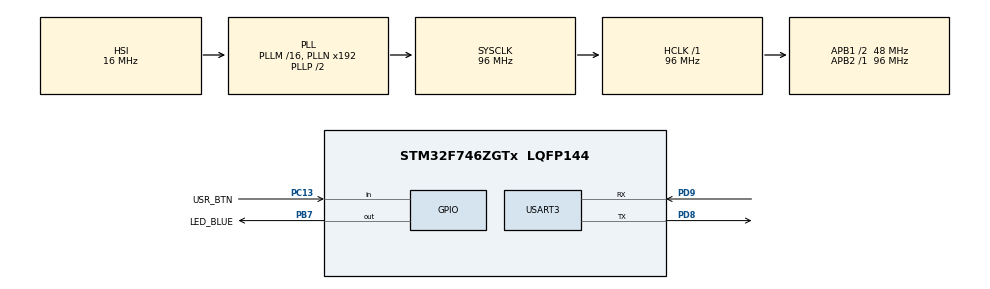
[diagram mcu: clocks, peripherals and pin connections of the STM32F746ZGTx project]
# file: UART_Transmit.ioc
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Mcu.Family=STM32F7
Mcu.Name=STM32F746ZGTx
Mcu.Package=LQFP144
NVIC.PriorityGroup=NVIC_PRIORITYGROUP_4
PB7.GPIO_Label=LED_BLUE
PB7.Signal=GPIO_Output
PC13.GPIO_Label=USR_BTN
PC13.Signal=GPIO_Input
PD8.Mode=Asynchronous
PD8.Signal=USART3_TX
PD9.Mode=Asynchronous
PD9.Signal=USART3_RX
ProjectManager.HeapSize=0x200
ProjectManager.StackSize=0x400
ProjectManager.TargetToolchain=STM32CubeIDE
RCC.AHBFreq_Value=96000000
RCC.APB1CLKDivider=RCC_HCLK_DIV2
RCC.APB1Freq_Value=48000000
RCC.APB1TimFreq_Value=96000000
RCC.APB2Freq_Value=96000000
RCC.APB2TimFreq_Value=96000000
RCC.CortexFreq_Value=96000000
RCC.HCLKFreq_Value=96000000
RCC.HSE_VALUE=25000000
RCC.HSI_VALUE=16000000
RCC.LSE_VALUE=32768
RCC.SYSCLKFreq_VALUE=96000000
RCC.SYSCLKSource=RCC_SYSCLKSOURCE_PLLCLK
RCC.USBFreq_Value=96000000
RCC.VCOOutputFreq_Value=192000000
USART3.VirtualMode-Asynchronous=VM_ASYNC
board=custom

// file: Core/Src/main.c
/* USER CODE BEGIN Header */
/**
  ******************************************************************************
  * @file           : main.c
  * @brief          : Main program body
  ******************************************************************************
  * @attention
  *
  * Copyright (c) 2024 STMicroelectronics.
  * All rights reserved.
  */
  /* This software is licensed under terms that can be found in the LICENSE file
  * in the root directory of this software component.
  * If no LICENSE file comes with this software, it is provided AS-IS.
  *
  * *****
  ******************************************************************************
  */
/* USER CODE END Header */
#include "main.h"
//

UART_HandleTypeDef huart3;

void SystemClock_Config(void);
static void MX_GPIO_Init(void);
static void MX_USART3_UART_Init(void);

/* USER CODE BEGIN 0 */
#define DATA_LEN	10

uint8_t Buffer[DATA_LEN] = {0x00, 0x01, 0x02, 0x03, 0x04, 0x05, 0x06, 0x07, 0x08, 0x09};
/* USER CODE END 0 */

int main(void)
{

  /* MCU Configuration--------------------------------------------------------*/

  /* Reset of all peripherals, Initializes the Flash interface and the Systick. */
  HAL_Init();

  /* Configure the system clock */
  SystemClock_Config();

  /* Initialize all configured peripherals */
  MX_GPIO_Init();
  MX_USART3_UART_Init();

  /* Infinite loop */
  /* USER CODE BEGIN WHILE */
  while (1)
  {
	  /* If button is pushed transmit data through uart and turn on LED for 1 sec */
	  if (HAL_GPIO_ReadPin(USR_BTN_GPIO_Port, USR_BTN_Pin) == GPIO_PIN_SET)
	  {
		  /* Transmit data and and turn on led for 1 sec */
		  HAL_UART_Transmit(&huart3, Buffer, DATA_LEN, 100);
		  HAL_GPIO_WritePin(LED_BLUE_GPIO_Port, LED_BLUE_Pin, GPIO_PIN_SET);
		  /* Delay */
		  HAL_Delay(2000);
	  }
	  HAL_GPIO_WritePin(LED_BLUE_GPIO_Port, LED_BLUE_Pin, GPIO_PIN_RESET);
    /* USER CODE END WHILE */

  }
}

void SystemClock_Config(void)
{
  RCC_OscInitTypeDef RCC_OscInitStruct = {0};
  RCC_ClkInitTypeDef RCC_ClkInitStruct = {0};

  /** Configure the main internal regulator output voltage
  */
  __HAL_RCC_PWR_CLK_ENABLE();
  __HAL_PWR_VOLTAGESCALING_CONFIG(PWR_REGULATOR_VOLTAGE_SCALE3);

  /** Initializes the RCC Oscillators according to the specified parameters
  * in the RCC_OscInitTypeDef structure.
  */
  RCC_OscInitStruct.OscillatorType = RCC_OSCILLATORTYPE_HSI;
  RCC_OscInitStruct.HSIState = RCC_HSI_ON;
  RCC_OscInitStruct.HSICalibrationValue = RCC_HSICALIBRATION_DEFAULT;
  RCC_OscInitStruct.PLL.PLLState = RCC_PLL_ON;
  RCC_OscInitStruct.PLL.PLLSource = RCC_PLLSOURCE_HSI;
  RCC_OscInitStruct.PLL.PLLM = 16;
  RCC_OscInitStruct.PLL.PLLN = 192;
  RCC_OscInitStruct.PLL.PLLP = RCC_PLLP_DIV2;
  RCC_OscInitStruct.PLL.PLLQ = 2;
  if (HAL_RCC_OscConfig(&RCC_OscInitStruct) != HAL_OK)
  {
    Error_Handler();
  }

  /** Activate the Over-Drive mode
  */
  if (HAL_PWREx_EnableOverDrive() != HAL_OK)
  {
    Error_Handler();
  }

  /** Initializes the CPU, AHB and APB buses clocks
  */
  RCC_ClkInitStruct.ClockType = RCC_CLOCKTYPE_HCLK|RCC_CLOCKTYPE_SYSCLK
                              |RCC_CLOCKTYPE_PCLK1|RCC_CLOCKTYPE_PCLK2;
  RCC_ClkInitStruct.SYSCLKSource = RCC_SYSCLKSOURCE_PLLCLK;
  RCC_ClkInitStruct.AHBCLKDivider = RCC_SYSCLK_DIV1;
  RCC_ClkInitStruct.APB1CLKDivider = RCC_HCLK_DIV2;
  RCC_ClkInitStruct.APB2CLKDivider = RCC_HCLK_DIV1;

  if (HAL_RCC_ClockConfig(&RCC_ClkInitStruct, FLASH_LATENCY_3) != HAL_OK)
  {
    Error_Handler();
  }
}

static void MX_USART3_UART_Init(void)
{

  huart3.Instance = USART3;
  huart3.Init.BaudRate = 115200;
  huart3.Init.WordLength = UART_WORDLENGTH_8B;
  huart3.Init.StopBits = UART_STOPBITS_1;
  huart3.Init.Parity = UART_PARITY_NONE;
  huart3.Init.Mode = UART_MODE_TX_RX;
  huart3.Init.HwFlowCtl = UART_HWCONTROL_NONE;
  huart3.Init.OverSampling = UART_OVERSAMPLING_16;
  huart3.Init.OneBitSampling = UART_ONE_BIT_SAMPLE_DISABLE;
  huart3.AdvancedInit.AdvFeatureInit = UART_ADVFEATURE_NO_INIT;
  if (HAL_UART_Init(&huart3) != HAL_OK)
  {
    Error_Handler();
  }

}

static void MX_GPIO_Init(void)
{
  GPIO_InitTypeDef GPIO_InitStruct = {0};

  /* GPIO Ports Clock Enable */
  __HAL_RCC_GPIOC_CLK_ENABLE();
  __HAL_RCC_GPIOD_CLK_ENABLE();
  __HAL_RCC_GPIOB_CLK_ENABLE();

  /*Configure GPIO pin Output Level */
  HAL_GPIO_WritePin(LED_BLUE_GPIO_Port, LED_BLUE_Pin, GPIO_PIN_RESET);

  /*Configure GPIO pin : USR_BTN_Pin */
  GPIO_InitStruct.Pin = USR_BTN_Pin;
  GPIO_InitStruct.Mode = GPIO_MODE_INPUT;
  GPIO_InitStruct.Pull = GPIO_NOPULL;
  HAL_GPIO_Init(USR_BTN_GPIO_Port, &GPIO_InitStruct);

  /*Configure GPIO pin : LED_BLUE_Pin */
  GPIO_InitStruct.Pin = LED_BLUE_Pin;
  GPIO_InitStruct.Mode = GPIO_MODE_OUTPUT_PP;
  GPIO_InitStruct.Pull = GPIO_NOPULL;
  GPIO_InitStruct.Speed = GPIO_SPEED_FREQ_LOW;
  HAL_GPIO_Init(LED_BLUE_GPIO_Port, &GPIO_InitStruct);

}

void Error_Handler(void)
{
  __disable_irq();
  while (1)
  {
  }
}
